AUTOSAR XML (schema 4-0-3)
package /ComponentTypes
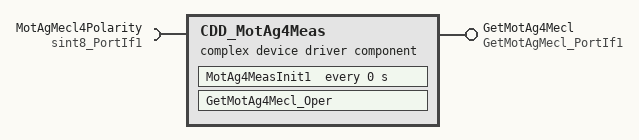
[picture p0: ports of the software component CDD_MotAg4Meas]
  complex device driver sw component type CDD_MotAg4Meas
    provide port GetMotAg4Mecl: server-com-spec{operation=Oper, queue-length=1}, provided-interface=GetMotAgMecl_PortIf1
    require port MotAgMecl4Polarity: nonqueued-receiver-com-spec{data-element=Val, filter=data-filter-type=ALWAYS, init-value=1}, required-interface=sint8_PortIf1  # Polarity value of Motor Angle 4
    behavior CDD_MotAg4Meas_InternalBehavior
      operation invoked event OIT_GetMotAg4Mecl_Oper_GetMotAg4Mecl_Oper: start-on-event=GetMotAg4Mecl_Oper, operation=GetMotAg4Mecl.Oper
      timing event CDD_MotAg4Meas_InitEvent: start-on-event=MotAg4MeasInit1, period=0
      runnable GetMotAg4Mecl_Oper
        data-receive-point-by-arguments:
          access REC_MotAgMecl4Polarity_Val: accessed-variable=MotAgMecl4Polarity.Val
      runnable MotAg4MeasInit1  # Initial Function for Motor Angle 4 Measurement
  swc implementation CDD_MotAg4Meas_Implementation: behavior=CDD_MotAg4Meas_InternalBehavior
    code-descriptors:
      code Default: artifact-descriptors=autosar-engineering-object={short-label=Default, category=SWSRC}
